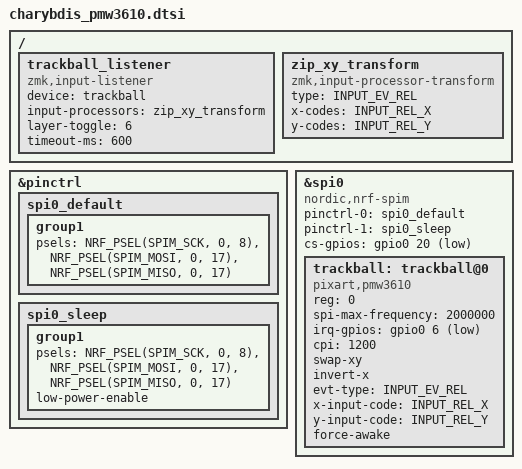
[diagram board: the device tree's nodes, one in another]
#include <dt-bindings/input/input-event-codes.h>

/ {
    trackball_listener: trackball_listener {
        compatible = "zmk,input-listener";
        device = <&trackball>;
        
        input-processors = <&zip_xy_transform>;
        
        // Automouse configuration
        layer-toggle = <6>;  // MOUSE layer
        timeout-ms = <600>;
    };
    
    zip_xy_transform: zip_xy_transform {
        compatible = "zmk,input-processor-transform";
        #input-processor-cells = <0>;
        type = <INPUT_EV_REL>;
        x-codes = <INPUT_REL_X>;
        y-codes = <INPUT_REL_Y>;
    };
};

&pinctrl {
    spi0_default: spi0_default {
        group1 {
            psels = <NRF_PSEL(SPIM_SCK, 0, 8)>,
                    <NRF_PSEL(SPIM_MOSI, 0, 17)>,
                    <NRF_PSEL(SPIM_MISO, 0, 17)>;
        };
    };

    spi0_sleep: spi0_sleep {
        group1 {
            psels = <NRF_PSEL(SPIM_SCK, 0, 8)>,
                    <NRF_PSEL(SPIM_MOSI, 0, 17)>,
                    <NRF_PSEL(SPIM_MISO, 0, 17)>;
            low-power-enable;
        };
    };
};

&spi0 {
    status = "okay";
    compatible = "nordic,nrf-spim";
    pinctrl-0 = <&spi0_default>;
    pinctrl-1 = <&spi0_sleep>;
    pinctrl-names = "default", "sleep";
    cs-gpios = <&gpio0 20 GPIO_ACTIVE_LOW>;

    trackball: trackball@0 {
        status = "okay";
        compatible = "pixart,pmw3610";
        reg = <0>;
        spi-max-frequency = <2000000>;
        irq-gpios = <&gpio0 6 (GPIO_ACTIVE_LOW | GPIO_PULL_UP)>;
        cpi = <1200>;
        swap-xy;
        invert-x;
        evt-type = <INPUT_EV_REL>;
        x-input-code = <INPUT_REL_X>;
        y-input-code = <INPUT_REL_Y>;
        force-awake;
    };
};
